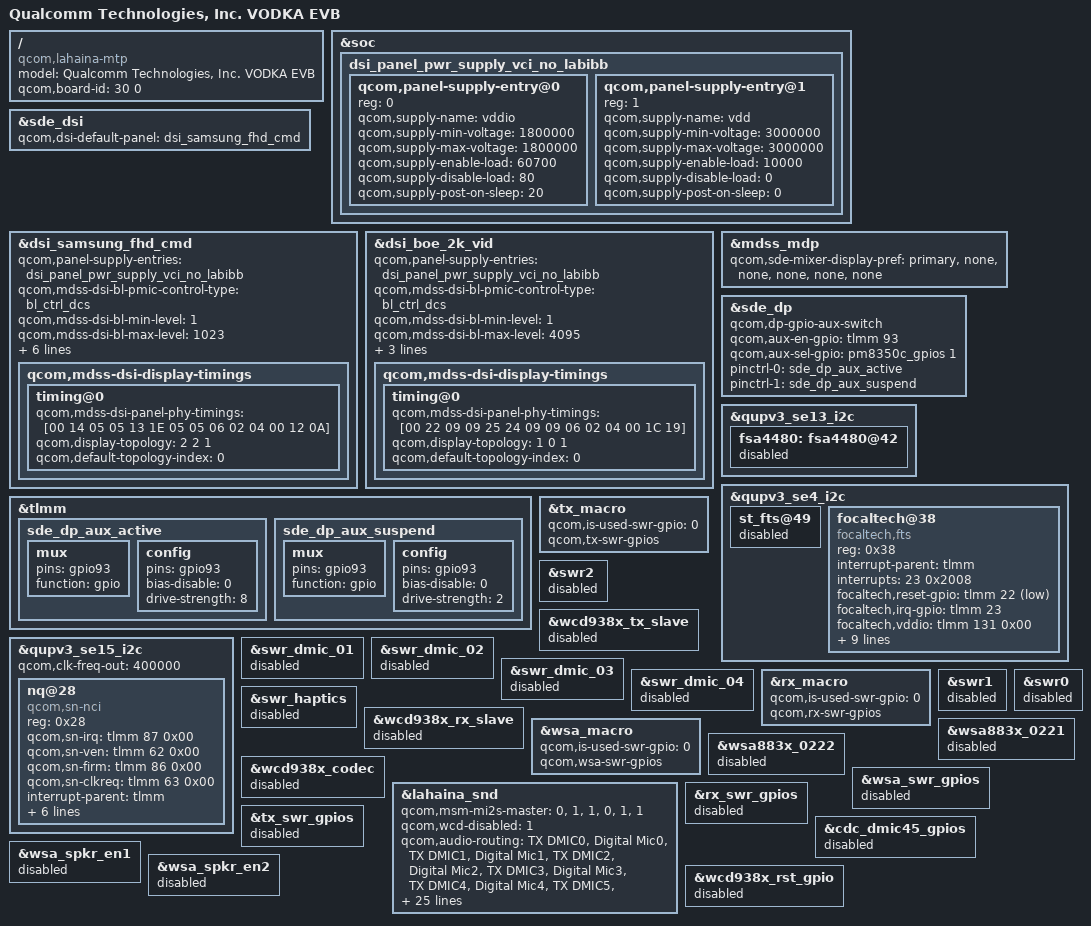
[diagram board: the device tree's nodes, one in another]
/dts-v1/;
/plugin/;

#include "lahaina-mtp.dtsi"
#include "dsi-panel-samsung-fhd-cmd.dtsi"
#include "dsi-panel-boe-2k-video.dtsi"

/ {
	model = "Qualcomm Technologies, Inc. VODKA EVB";
	compatible = "qcom,lahaina-mtp", "qcom,lahaina", "qcom,mtp";
	qcom,board-id = <30 0>;
};

/*   ====================================
*    overlay for display - start
*    ====================================
*/

&soc {
	dsi_panel_pwr_supply_vci_no_labibb: dsi_panel_pwr_supply_vci_no_labibb {
		#address-cells = <1>;
		#size-cells = <0>;

		qcom,panel-supply-entry@0 {
			reg = <0>;
			qcom,supply-name = "vddio";
			qcom,supply-min-voltage = <1800000>;
			qcom,supply-max-voltage = <1800000>;
			qcom,supply-enable-load = <60700>;
			qcom,supply-disable-load = <80>;
			qcom,supply-post-on-sleep = <20>;
		};

		qcom,panel-supply-entry@1 {
			reg = <1>;
			qcom,supply-name = "vdd";
			qcom,supply-min-voltage = <3000000>;
			qcom,supply-max-voltage = <3000000>;
			qcom,supply-enable-load = <10000>;
			qcom,supply-disable-load = <0>;
			qcom,supply-post-on-sleep = <0>;
		};
	};

};

&sde_dsi {
	/delete-property/ avdd-supply;
	qcom,dsi-default-panel = <&dsi_samsung_fhd_cmd>;

};

&dsi_samsung_fhd_cmd {
	qcom,panel-supply-entries = <&dsi_panel_pwr_supply_vci_no_labibb>;
	qcom,mdss-dsi-bl-pmic-control-type = "bl_ctrl_dcs";
	qcom,mdss-dsi-bl-min-level = <1>;
	qcom,mdss-dsi-bl-max-level = <1023>;

	qcom,platform-te-gpio = <&tlmm 82 0>; // default is 82
	qcom,platform-reset-gpio = <&tlmm 24 0>;
	qcom,platform-en-gpio = <&tlmm 14 0>;

	qcom,ulps-enabled;
	qcom,dsi-select-clocks = "mux_byte_clk0", "mux_pixel_clk0";
	qcom,mdss-dsi-display-timings {
		timing@0 {
			qcom,mdss-dsi-panel-phy-timings = [00 14 05 05 13 1E 05
				05 06 02 04 00 12 0A];
			qcom,display-topology = <2 2 1>;
			qcom,default-topology-index = <0>;
		};
	};
};

&dsi_boe_2k_vid {
	qcom,panel-supply-entries = <&dsi_panel_pwr_supply_vci_no_labibb>;
	qcom,mdss-dsi-bl-pmic-control-type = "bl_ctrl_dcs";
	qcom,mdss-dsi-bl-min-level = <1>;
	qcom,mdss-dsi-bl-max-level = <4095>;
	qcom,mdss-dsi-mode-sel-gpio-state = "single_port";
	qcom,platform-te-gpio = <&tlmm 82 0>; // default is 82
	qcom,platform-reset-gpio = <&tlmm 24 0>;

	qcom,mdss-dsi-display-timings {
		timing@0 {
			qcom,mdss-dsi-panel-phy-timings = [00 22 09 09 25 24 09
				09 06 02 04 00 1C 19];
			qcom,display-topology = <1 0 1>;
			qcom,default-topology-index = <0>;
		};
	};
};

&mdss_mdp {
	qcom,sde-mixer-display-pref = "primary", "none", "none",
				"none", "none", "none";
};

&sde_dp {
	/delete-property/ qcom,dp-aux-switch;
	qcom,dp-gpio-aux-switch;

	qcom,aux-en-gpio = <&tlmm 93 0>;
	qcom,aux-sel-gpio = <&pm8350c_gpios 1 0x0>;


	pinctrl-names = "mdss_dp_active", "mdss_dp_sleep";
	pinctrl-0 = <&sde_dp_aux_active >;
	pinctrl-1 = <&sde_dp_aux_suspend>;
};

&tlmm {
	/delete-property/ display_panel_avdd_default;

	sde_dp_aux_active: sde_dp_aux_active {
		mux {
			pins = "gpio93";
			function = "gpio";
		};

		config {
			pins = "gpio93";
			bias-disable = <0>; /* no pull */
			drive-strength = <8>;
		};
	};

	sde_dp_aux_suspend: sde_dp_aux_suspend {
		mux {
			pins = "gpio93";
			function = "gpio";
		};

		config {
			pins = "gpio93";
			bias-disable = <0>; /* no pull */
			drive-strength = <2>;
		};
	};
};

&qupv3_se13_i2c {
	fsa4480: fsa4480@42 {
		status = "disable";
	};
};

// Touch_BSP FT3518U +++
&qupv3_se4_i2c {
	status = "ok";
//	/delete-property/ qcom,i2c-touch-active;

	st_fts@49 {
		status = "disable";
	};

	focaltech@38{
		compatible = "focaltech,fts";
		reg = <0x38>;
		interrupt-parent = <&tlmm>;
		interrupts = <23 0x2008>;
		focaltech,reset-gpio = <&tlmm 22 0x01>;
		focaltech,irq-gpio = <&tlmm 23 0x2008>;
		focaltech,vddio = <&tlmm 131 0x00>;
		focaltech,max-touch-number = <10>;
		focaltech,display-coords = <0 0 1080 2400>;

		vdd-supply = <&L3C>;
		focaltech,regulator_dvdd = "vdd";
		vcc_i2c-supply = <&L8C>;
		focaltech,regulator_dvcc_i2c = "vcc_i2c";

		pinctrl-names = "pmx_ts_active", "pmx_ts_suspend","pmx_ts_release";
		pinctrl-0 = <&ts_active>;
		pinctrl-1 = <&ts_int_suspend &ts_reset_suspend>;
		pinctrl-2 = <&ts_release>;
	};
};

// Touch_BSP FT3518U ---

/*   ====================================
*    overlay for display - end
*    ====================================
*/

/*    ====================================
 *    overlay for lahainap-v2.dtsi - start
 *    ====================================
 */

/*    ====================================
 *    overlay for lahainap-v2.dtsi - end
 *    ====================================
 */



/*    ====================================
 *    overlay for lahainap.dtsi - start
 *    ====================================
 */

/*    ====================================
 *    overlay for lahainap.dtsi - end
 *    ====================================
 */



/*    ====================================
 *    overlay for lahaina-mtp.dtsi - start
 *    ====================================
 */

&qupv3_se15_i2c{
	status = "ok";
	qcom,clk-freq-out = <400000>;

	nq@28 {
		compatible = "qcom,sn-nci";
		reg = <0x28>;
		qcom,sn-irq = <&tlmm 87 0x00>;
		qcom,sn-ven = <&tlmm 62 0x00>;
		qcom,sn-firm = <&tlmm 86 0x00>;
		qcom,sn-clkreq = <&tlmm 63 0x00>;
		interrupt-parent = <&tlmm>;
		interrupts = <87 0>;
		interrupt-names = "nfc_irq";
		pinctrl-names = "nfc_active", "nfc_suspend";
		pinctrl-0 = <&nfc_int_active &nfc_enable_active
				&nfc_clk_req_active &nfc_fwdl_active>;
		pinctrl-1 = <&nfc_int_suspend &nfc_enable_suspend
				&nfc_clk_req_suspend &nfc_fwdl_suspend>;
	};
};

/*    ====================================
 *    overlay for lahaina-mtp.dtsi - end
 *    ====================================
 */


/*    ====================================
 *    overlay for lahaina-pm.dtsi - start
 *    ====================================
 */

/*    ====================================
 *    overlay for lahaina-pm.dtsi - end
 *    ====================================
 */



/*    ====================================
 *    overlay for lahaina-pinctrl.dtsi - start
 *    ====================================
 */

/*    ====================================
 *    overlay for lahaina-pinctrl.dtsi - end
 *    ====================================
 */



/*    ====================================
 *    overlay for lahaina-pmic-overlay.dtsi - start
 *    ====================================
 */

/*    ====================================
 *    overlay for lahaina-pmic-overlay.dtsi - end
 *    ====================================
 */


/*    ====================================
 *    overlay for pm8350.dtsi - start
 *    ====================================
 */

/*    ====================================
 *    overlay for pm8350.dtsi - end
 *    ====================================
 */


/*    ====================================
 *    overlay for pmk8350.dtsi - start
 *    ====================================
 */

/*    ====================================
 *    overlay for pmk8350.dtsi - end
 *    ====================================
 */

/*    ====================================
 *    overlay for pm8350b.dtsi - start
 *    ====================================
 */

/*    ====================================
 *    overlay for pm8350b.dtsi - end
 *    ====================================
 */

/*    ====================================
 *    overlay for pm8350c.dtsi - start
 *    ====================================
 */

/*    ====================================
 *    overlay for pm8350c.dtsi - end
 *    ====================================
 */


/*    ====================================
 *    overlay for lahaina-regulators.dtsi - start
 *    ====================================
 */

/*    ====================================
 *    overlay for lahaina-regulators.dtsi - end
 *    ====================================
 */
  

 
/*    ====================================
 *    overlay for lahaina-audio.dtsi - start
 *    ====================================
 */

&tx_macro {
	qcom,is-used-swr-gpio = <0>;
	qcom,tx-swr-gpios;
};

&swr2 {
	status = "disabled";
};

&wcd938x_tx_slave {
	status = "disabled";
};

&swr_dmic_01 {
	status = "disabled";
};

&swr_dmic_02 {
	status = "disabled";
};

&swr_dmic_03 {
	status = "disabled";
};

&swr_dmic_04 {
	status = "disabled";
};

&rx_macro {
	qcom,is-used-swr-gpio = <0>;
	qcom,rx-swr-gpios;
};

&swr1 {
	status = "disabled";
};

&swr_haptics {
	status = "disabled";
};

&wcd938x_rx_slave {
	status = "disabled";
};

&wsa_macro {
	qcom,is-used-swr-gpio = <0>;
	qcom,wsa-swr-gpios;
};

&swr0 {
	status = "disabled";
};

&wsa883x_0221 {
	status = "disabled";
};

&wsa883x_0222 {
	status = "disabled";
};

&wcd938x_codec {
	status = "disabled";
};

&lahaina_snd {
	qcom,msm-mi2s-master = <0>, <1>, <1>, <0>, <1>, <1>;
	qcom,wcd-disabled = <1>;
	qcom,audio-routing =
		"TX DMIC0", "Digital Mic0",
		"TX DMIC1", "Digital Mic1",
		"TX DMIC2", "Digital Mic2",
		"TX DMIC3", "Digital Mic3",
		"TX DMIC4", "Digital Mic4",
		"TX DMIC5", "Digital Mic5",
		"WSA SRC0_INP", "SRC0",
		"WSA_TX DEC0_INP", "TX DEC0 MUX",
		"WSA_TX DEC1_INP", "TX DEC1 MUX",
		"RX_TX DEC0_INP", "TX DEC0 MUX",
		"RX_TX DEC1_INP", "TX DEC1 MUX",
		"RX_TX DEC2_INP", "TX DEC2 MUX",
		"RX_TX DEC3_INP", "TX DEC3 MUX",
		"VA SWR_INPUT", "VA_SWR_CLK",
		"VA_AIF1 CAP", "VA_SWR_CLK",
		"VA_AIF2 CAP", "VA_SWR_CLK",
		"VA_AIF3 CAP", "VA_SWR_CLK",
		"VA DMIC0", "Digital Mic0",
		"VA DMIC1", "Digital Mic1",
		"VA DMIC2", "Digital Mic2",
		"VA DMIC3", "Digital Mic3",
		"VA DMIC4", "Digital Mic4",
		"VA DMIC5", "Digital Mic5",
		"Digital Mic0", "VA MIC BIAS1",
		"Digital Mic1", "VA MIC BIAS1",
		"Digital Mic2", "VA MIC BIAS1",
		"Digital Mic3", "VA MIC BIAS1",
		"Digital Mic4", "VA MIC BIAS1",
		"Digital Mic5", "VA MIC BIAS1";
	qcom,msm-mbhc-hphl-swh;
	qcom,msm-mbhc-gnd-swh;
	qcom,cdc-dmic45-gpios;
	asoc-codec  = <&stub_codec>, <&bolero>,
		      <&ext_disp_audio_codec>;
	asoc-codec-names = "msm-stub-codec.1", "bolero_codec",
			   "msm-ext-disp-audio-codec-rx";
	qcom,wsa-max-devs;
};

&wsa_swr_gpios {
	status = "disabled";
};

&rx_swr_gpios {
	status = "disabled";
};

&tx_swr_gpios {
	status = "disabled";
};

&cdc_dmic45_gpios {
	status = "disabled";
};

&wsa_spkr_en1 {
	status = "disabled";
};

&wsa_spkr_en2 {
	status = "disabled";
};

&wcd938x_rst_gpio {
	status = "disabled";
};

/*    ====================================
 *    overlay for lahaina-audio.dtsi - end
 *    ====================================
 */

/*    ====================================
 *    overlay for lahaina-audio-overlay.dtsi - start
 *    ====================================
 */

/*    ====================================
 *    overlay for lahaina-audio-overlay.dtsi - end
 *    ====================================
 */


/*    ====================================
 *    overlay for lahaina-thermal-overlay.dtsi - start
 *    ====================================
 */

/*    ====================================
 *    overlay for lahaina-thermal-overlay.dtsi - end
 *    ====================================
 */

 
/*    ====================================
 *    overlay for lahaina-gpu.dtsi - start
 *    ====================================
 */

/*    ====================================
 *    overlay for lahaina-gpu.dtsi - end
 *    ====================================
 */


/*    ====================================
 *    overlay for lahaina-usb.dtsi - start
 *    ====================================
 */

/*    ====================================
 *    overlay for lahaina-usb.dtsi - end
 *    ====================================
 */
 
